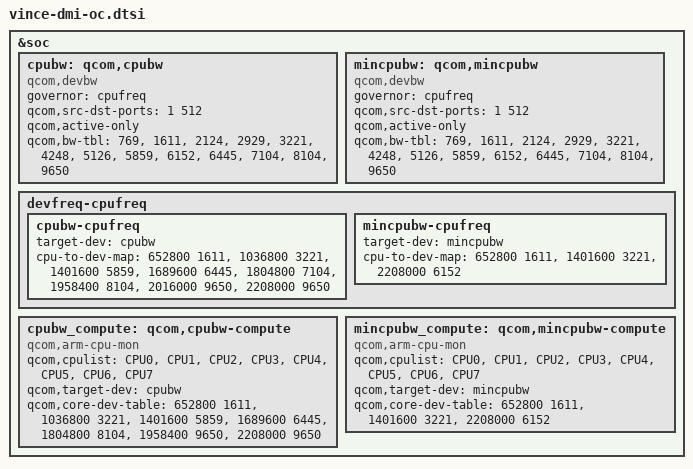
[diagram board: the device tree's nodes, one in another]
/*
 * Copyright (c) 2015-2017, The Linux Foundation. All rights reserved.
 *
 * This program is free software; you can redistribute it and/or modify
 * it under the terms of the GNU General Public License version 2 and
 * only version 2 as published by the Free Software Foundation.
 *
 * This program is distributed in the hope that it will be useful,
 * but WITHOUT ANY WARRANTY; without even the implied warranty of
 * MERCHANTABILITY or FITNESS FOR A PARTICULAR PURPOSE.  See the
 * GNU General Public License for more details.
 */

&soc {
		cpubw: qcom,cpubw {
		compatible = "qcom,devbw";
		governor = "cpufreq";
		qcom,src-dst-ports = <1 512>;
		qcom,active-only;
		qcom,bw-tbl =
			<   769 /*  100.8 MHz */ >,
			<  1611 /*  211.2 MHz */ >,     /*Low SVS*/
			<  2124 /*  278.4 MHz */ >,
			<  2929 /*  384   MHz */ >,
			<  3221 /*  422.4 MHz */ >,	/* SVS */
			<  4248 /*  556.8 MHz */ >,
			<  5126 /*  672   MHz */ >,
			<  5859 /*  768   MHz */ >,     /* SVS+  */
			<  6152 /*  806.4 MHz */ >,
			<  6445 /*  844.8 MHz */ >,     /* NOM   */
			<  7104 /*  931.2 MHz */ >,     /* TURBO */
			<  8104 /*  NON CALC  */ >,
			<  9650 /*  NON CALC  */ >;
	};

	mincpubw: qcom,mincpubw {
		compatible = "qcom,devbw";
		governor = "cpufreq";
		qcom,src-dst-ports = <1 512>;
		qcom,active-only;
		qcom,bw-tbl =
			<   769 /*  100.8 MHz */ >,
			<  1611 /*  211.2 MHz */ >,     /*Low SVS*/
			<  2124 /*  278.4 MHz */ >,
			<  2929 /*  384   MHz */ >,
			<  3221 /*  422.4 MHz */ >,	/* SVS */
			<  4248 /*  556.8 MHz */ >,
			<  5126 /*  672   MHz */ >,
			<  5859 /*  768   MHz */ >,     /* SVS+  */
			<  6152 /*  806.4 MHz */ >,
			<  6445 /*  844.8 MHz */ >,     /* NOM   */
			<  7104 /*  931.2 MHz */ >,     /* TURBO */
			<  8104 /*  NON CALC  */ >,
			<  9650 /*  NON CALC  */ >;
	};

	devfreq-cpufreq {
		cpubw-cpufreq {
		target-dev = <&cpubw>;
		cpu-to-dev-map =
			 <  652800  1611>,
			 < 1036800  3221>,
			 < 1401600  5859>,
			 < 1689600  6445>,
			 < 1804800  7104>,
			 < 1958400  8104>,
			 < 2016000  9650>,
			 < 2208000  9650>;
		};

		mincpubw-cpufreq {
			target-dev = <&mincpubw>;
			cpu-to-dev-map =
				<  652800 1611 >,
				< 1401600 3221 >,
				< 2208000 6152 >;
		};
	};

	cpubw_compute: qcom,cpubw-compute {
		compatible = "qcom,arm-cpu-mon";
		qcom,cpulist = < &CPU0 &CPU1 &CPU2 &CPU3
				&CPU4 &CPU5 &CPU6 &CPU7 >;
		qcom,target-dev = <&cpubw>;
		qcom,core-dev-table =
				 <  652800  1611>,
				 < 1036800  3221>,
				 < 1401600  5859>,
				 < 1689600  6445>,
				 < 1804800  8104>,
				 < 1958400  9650>,
				 < 2208000  9650>;
	};

	mincpubw_compute: qcom,mincpubw-compute {
		compatible = "qcom,arm-cpu-mon";
		qcom,cpulist = < &CPU0 &CPU1 &CPU2 &CPU3
				&CPU4 &CPU5 &CPU6 &CPU7 >;
		qcom,target-dev = <&mincpubw>;
		qcom,core-dev-table =
				<  652800 1611 >,
				< 1401600 3221 >,
				< 2208000 6152 >;
	};
};
